AUTOSAR XML (schema 4-2-2)
package /STELLANTIS/EPT/ASWCs
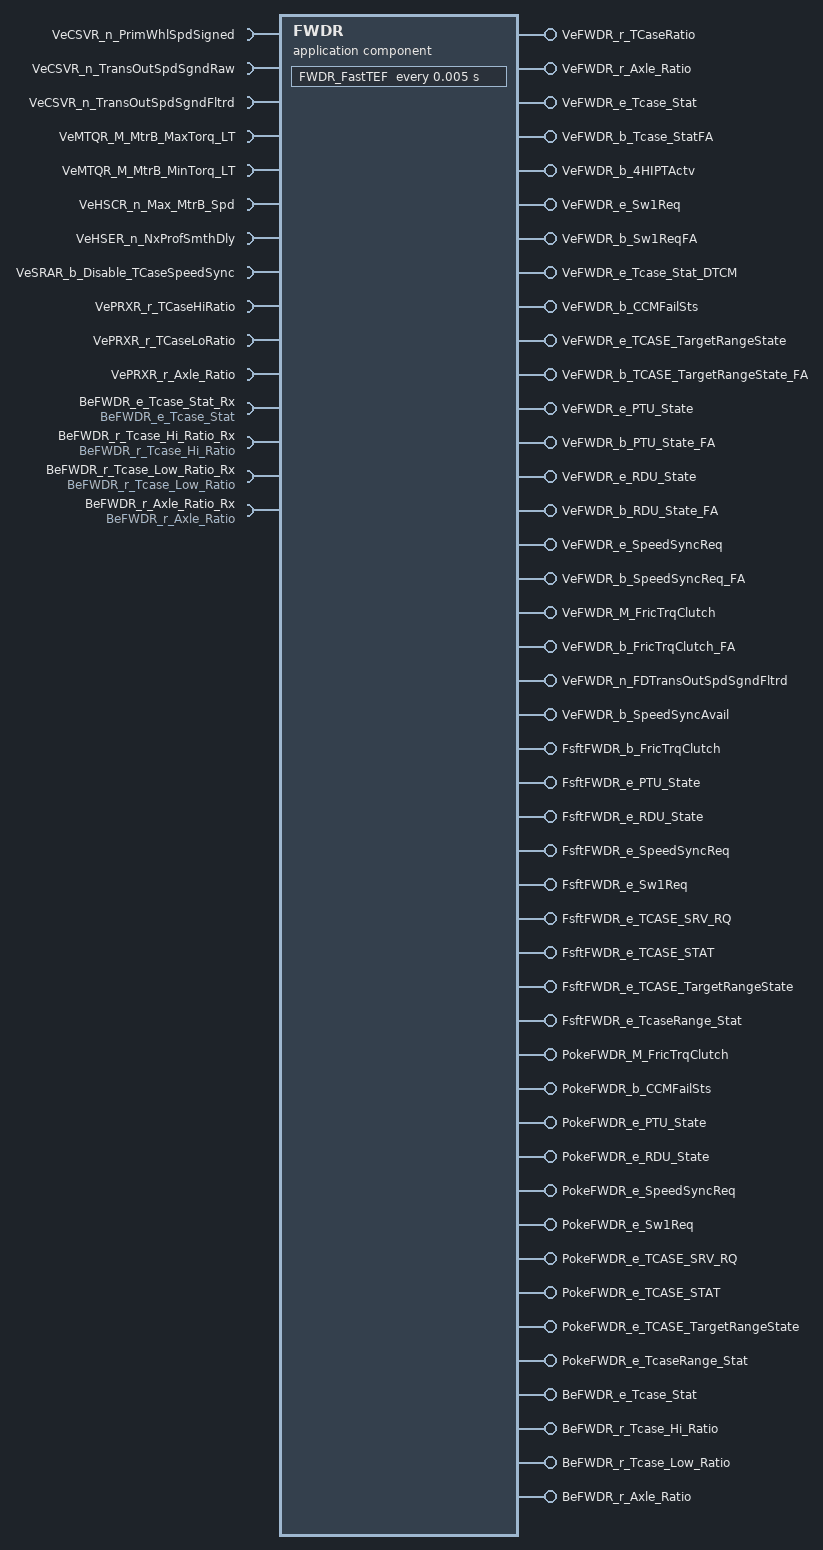
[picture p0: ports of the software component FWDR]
  application sw component type FWDR
    11 x require port, all with nonqueued-receiver-com-spec{data-element=Value, init-value=0}:
      VeCSVR_n_PrimWhlSpdSigned: required-interface=VeCSVR_n_PrimWhlSpdSigned
      VeCSVR_n_TransOutSpdSgndRaw: required-interface=VeCSVR_n_TransOutSpdSgndRaw
      VeCSVR_n_TransOutSpdSgndFltrd: required-interface=VeCSVR_n_TransOutSpdSgndFltrd
      VeMTQR_M_MtrB_MaxTorq_LT: required-interface=VeMTQR_M_MtrB_MaxTorq_LT
      VeMTQR_M_MtrB_MinTorq_LT: required-interface=VeMTQR_M_MtrB_MinTorq_LT
      VeHSCR_n_Max_MtrB_Spd: required-interface=VeHSCR_n_Max_MtrB_Spd
      VeHSER_n_NxProfSmthDly: required-interface=VeHSER_n_NxProfSmthDly
      VeSRAR_b_Disable_TCaseSpeedSync: required-interface=VeSRAR_b_Disable_TCaseSpeedSync
      VePRXR_r_TCaseHiRatio: required-interface=VePRXR_r_TCaseHiRatio
      VePRXR_r_TCaseLoRatio: required-interface=VePRXR_r_TCaseLoRatio
      VePRXR_r_Axle_Ratio: required-interface=VePRXR_r_Axle_Ratio
    40 x provide port:
      VeFWDR_r_TCaseRatio: nonqueued-sender-com-spec{data-element=Value, init-value=0}, provided-interface=VeFWDR_r_TCaseRatio
      VeFWDR_r_Axle_Ratio: nonqueued-sender-com-spec{data-element=Value, init-value=0}, provided-interface=VeFWDR_r_Axle_Ratio
      VeFWDR_e_Tcase_Stat: nonqueued-sender-com-spec{data-element=Value, init-value=CeFWDR_e_ShiftINProg}, provided-interface=VeFWDR_e_Tcase_Stat
      VeFWDR_b_Tcase_StatFA: nonqueued-sender-com-spec{data-element=Value, init-value=0}, provided-interface=VeFWDR_b_Tcase_StatFA
      VeFWDR_b_4HIPTActv: nonqueued-sender-com-spec{data-element=Value, init-value=0}, provided-interface=VeFWDR_b_4HIPTActv
      VeFWDR_e_Sw1Req: nonqueued-sender-com-spec{data-element=Value, init-value=CeFWDR_e_NotPSD}, provided-interface=VeFWDR_e_Sw1Req
      VeFWDR_b_Sw1ReqFA: nonqueued-sender-com-spec{data-element=Value, init-value=0}, provided-interface=VeFWDR_b_Sw1ReqFA
      VeFWDR_e_Tcase_Stat_DTCM: nonqueued-sender-com-spec{data-element=Value, init-value=CeFWDR_e_ShiftINProg}, provided-interface=VeFWDR_e_Tcase_Stat_DTCM
      VeFWDR_b_CCMFailSts: nonqueued-sender-com-spec{data-element=Value, init-value=0}, provided-interface=VeFWDR_b_CCMFailSts
      VeFWDR_e_TCASE_TargetRangeState: nonqueued-sender-com-spec{data-element=Value, init-value=CeFWDR_e_TRS_High}, provided-interface=VeFWDR_e_TCASE_TargetRangeState
      VeFWDR_b_TCASE_TargetRangeState_FA: nonqueued-sender-com-spec{data-element=Value, init-value=0}, provided-interface=VeFWDR_b_TCASE_TargetRangeState_FA
      VeFWDR_e_PTU_State: nonqueued-sender-com-spec{data-element=Value, init-value=CeFWDR_e_PTU_SNA}, provided-interface=VeFWDR_e_PTU_State
      VeFWDR_b_PTU_State_FA: nonqueued-sender-com-spec{data-element=Value, init-value=0}, provided-interface=VeFWDR_b_PTU_State_FA
      VeFWDR_e_RDU_State: nonqueued-sender-com-spec{data-element=Value, init-value=CeFWDR_e_RDU_SNA}, provided-interface=VeFWDR_e_RDU_State
      VeFWDR_b_RDU_State_FA: nonqueued-sender-com-spec{data-element=Value, init-value=0}, provided-interface=VeFWDR_b_RDU_State_FA
      VeFWDR_e_SpeedSyncReq: nonqueued-sender-com-spec{data-element=Value, init-value=CeFWDR_e_SSR_Inactive}, provided-interface=VeFWDR_e_SpeedSyncReq
      VeFWDR_b_SpeedSyncReq_FA: nonqueued-sender-com-spec{data-element=Value, init-value=0}, provided-interface=VeFWDR_b_SpeedSyncReq_FA
      VeFWDR_M_FricTrqClutch: nonqueued-sender-com-spec{data-element=Value, init-value=0}, provided-interface=VeFWDR_M_FricTrqClutch
      VeFWDR_b_FricTrqClutch_FA: nonqueued-sender-com-spec{data-element=Value, init-value=0}, provided-interface=VeFWDR_b_FricTrqClutch_FA
      VeFWDR_n_FDTransOutSpdSgndFltrd: nonqueued-sender-com-spec{data-element=Value, init-value=0}, provided-interface=VeFWDR_n_FDTransOutSpdSgndFltrd
      VeFWDR_b_SpeedSyncAvail: nonqueued-sender-com-spec{data-element=Value, init-value=0}, provided-interface=VeFWDR_b_SpeedSyncAvail
      FsftFWDR_b_FricTrqClutch: server-com-spec=FsftFWDR_b_FricTrqClutch, provided-interface=FsftFWDR_b_FricTrqClutch
      FsftFWDR_e_PTU_State: server-com-spec=FsftFWDR_e_PTU_State, provided-interface=FsftFWDR_e_PTU_State
      FsftFWDR_e_RDU_State: server-com-spec=FsftFWDR_e_RDU_State, provided-interface=FsftFWDR_e_RDU_State
      FsftFWDR_e_SpeedSyncReq: server-com-spec=FsftFWDR_e_SpeedSyncReq, provided-interface=FsftFWDR_e_SpeedSyncReq
      FsftFWDR_e_Sw1Req: server-com-spec=FsftFWDR_e_Sw1Req, provided-interface=FsftFWDR_e_Sw1Req
      FsftFWDR_e_TCASE_SRV_RQ: server-com-spec=FsftFWDR_e_TCASE_SRV_RQ, provided-interface=FsftFWDR_e_TCASE_SRV_RQ
      FsftFWDR_e_TCASE_STAT: server-com-spec=FsftFWDR_e_TCASE_STAT, provided-interface=FsftFWDR_e_TCASE_STAT
      FsftFWDR_e_TCASE_TargetRangeState: server-com-spec=FsftFWDR_e_TCASE_TargetRangeState, provided-interface=FsftFWDR_e_TCASE_TargetRangeState
      FsftFWDR_e_TcaseRange_Stat: server-com-spec=FsftFWDR_e_TcaseRange_Stat, provided-interface=FsftFWDR_e_TcaseRange_Stat
      PokeFWDR_M_FricTrqClutch: server-com-spec{operation=PokeFWDR_M_FricTrqClutch, queue-length=1}, provided-interface=PokeFWDR_M_FricTrqClutch
      PokeFWDR_b_CCMFailSts: server-com-spec{operation=PokeFWDR_b_CCMFailSts, queue-length=1}, provided-interface=PokeFWDR_b_CCMFailSts
      PokeFWDR_e_PTU_State: server-com-spec{operation=PokeFWDR_e_PTU_State, queue-length=1}, provided-interface=PokeFWDR_e_PTU_State
      PokeFWDR_e_RDU_State: server-com-spec{operation=PokeFWDR_e_RDU_State, queue-length=1}, provided-interface=PokeFWDR_e_RDU_State
      PokeFWDR_e_SpeedSyncReq: server-com-spec{operation=PokeFWDR_e_SpeedSyncReq, queue-length=1}, provided-interface=PokeFWDR_e_SpeedSyncReq
      PokeFWDR_e_Sw1Req: server-com-spec{operation=PokeFWDR_e_Sw1Req, queue-length=1}, provided-interface=PokeFWDR_e_Sw1Req
      PokeFWDR_e_TCASE_SRV_RQ: server-com-spec{operation=PokeFWDR_e_TCASE_SRV_RQ, queue-length=1}, provided-interface=PokeFWDR_e_TCASE_SRV_RQ
      PokeFWDR_e_TCASE_STAT: server-com-spec{operation=PokeFWDR_e_TCASE_STAT, queue-length=1}, provided-interface=PokeFWDR_e_TCASE_STAT
      PokeFWDR_e_TCASE_TargetRangeState: server-com-spec{operation=PokeFWDR_e_TCASE_TargetRangeState, queue-length=1}, provided-interface=PokeFWDR_e_TCASE_TargetRangeState
      PokeFWDR_e_TcaseRange_Stat: server-com-spec{operation=PokeFWDR_e_TcaseRange_Stat, queue-length=1}, provided-interface=PokeFWDR_e_TcaseRange_Stat
    4 x require port:
      BeFWDR_e_Tcase_Stat_Rx: nv-require-com-spec{init-value=-10, variable=BeFWDR_e_Tcase_Stat}, required-interface=BeFWDR_e_Tcase_Stat
      BeFWDR_r_Tcase_Hi_Ratio_Rx: nv-require-com-spec{init-value=-10, variable=BeFWDR_r_Tcase_Hi_Ratio}, required-interface=BeFWDR_r_Tcase_Hi_Ratio
      BeFWDR_r_Tcase_Low_Ratio_Rx: nv-require-com-spec{init-value=-10, variable=BeFWDR_r_Tcase_Low_Ratio}, required-interface=BeFWDR_r_Tcase_Low_Ratio
      BeFWDR_r_Axle_Ratio_Rx: nv-require-com-spec{init-value=-10, variable=BeFWDR_r_Axle_Ratio}, required-interface=BeFWDR_r_Axle_Ratio
    4 x provide port:
      BeFWDR_e_Tcase_Stat: nv-provide-com-spec{ram-block-init-value=-10, variable=BeFWDR_e_Tcase_Stat}, provided-interface=BeFWDR_e_Tcase_Stat
      BeFWDR_r_Tcase_Hi_Ratio: nv-provide-com-spec{ram-block-init-value=-10, variable=BeFWDR_r_Tcase_Hi_Ratio}, provided-interface=BeFWDR_r_Tcase_Hi_Ratio
      BeFWDR_r_Tcase_Low_Ratio: nv-provide-com-spec{ram-block-init-value=-10, variable=BeFWDR_r_Tcase_Low_Ratio}, provided-interface=BeFWDR_r_Tcase_Low_Ratio
      BeFWDR_r_Axle_Ratio: nv-provide-com-spec{ram-block-init-value=-10, variable=BeFWDR_r_Axle_Ratio}, provided-interface=BeFWDR_r_Axle_Ratio
    behavior IB_FWDR: data-type-mapping=msADTtoIDTMapping, handle-termination-and-restart=NO-SUPPORT
      timing event Event_FastTEF: start-on-event=FWDR_FastTEF, period=0.005
      19 x operation invoked event:
        Event_FsftFWDR_b_FricTrqClutch: start-on-event=FsftFWDR_b_FricTrqClutch, operation=FsftFWDR_b_FricTrqClutch.FsftFWDR_b_FricTrqClutch
        Event_FsftFWDR_e_PTU_State: start-on-event=FsftFWDR_e_PTU_State, operation=FsftFWDR_e_PTU_State.FsftFWDR_e_PTU_State
        Event_FsftFWDR_e_RDU_State: start-on-event=FsftFWDR_e_RDU_State, operation=FsftFWDR_e_RDU_State.FsftFWDR_e_RDU_State
        Event_FsftFWDR_e_SpeedSyncReq: start-on-event=FsftFWDR_e_SpeedSyncReq, operation=FsftFWDR_e_SpeedSyncReq.FsftFWDR_e_SpeedSyncReq
        Event_FsftFWDR_e_Sw1Req: start-on-event=FsftFWDR_e_Sw1Req, operation=FsftFWDR_e_Sw1Req.FsftFWDR_e_Sw1Req
        Event_FsftFWDR_e_TCASE_SRV_RQ: start-on-event=FsftFWDR_e_TCASE_SRV_RQ, operation=FsftFWDR_e_TCASE_SRV_RQ.FsftFWDR_e_TCASE_SRV_RQ
        Event_FsftFWDR_e_TCASE_STAT: start-on-event=FsftFWDR_e_TCASE_STAT, operation=FsftFWDR_e_TCASE_STAT.FsftFWDR_e_TCASE_STAT
        Event_FsftFWDR_e_TCASE_TargetRangeState: start-on-event=FsftFWDR_e_TCASE_TargetRangeState, operation=FsftFWDR_e_TCASE_TargetRangeState.FsftFWDR_e_TCASE_TargetRangeState
        Event_FsftFWDR_e_TcaseRange_Stat: start-on-event=FsftFWDR_e_TcaseRange_Stat, operation=FsftFWDR_e_TcaseRange_Stat.FsftFWDR_e_TcaseRange_Stat
        Event_PokeFWDR_M_FricTrqClutch: start-on-event=PokeFWDR_M_FricTrqClutch, operation=PokeFWDR_M_FricTrqClutch.PokeFWDR_M_FricTrqClutch
        Event_PokeFWDR_b_CCMFailSts: start-on-event=PokeFWDR_b_CCMFailSts, operation=PokeFWDR_b_CCMFailSts.PokeFWDR_b_CCMFailSts
        Event_PokeFWDR_e_PTU_State: start-on-event=PokeFWDR_e_PTU_State, operation=PokeFWDR_e_PTU_State.PokeFWDR_e_PTU_State
        Event_PokeFWDR_e_RDU_State: start-on-event=PokeFWDR_e_RDU_State, operation=PokeFWDR_e_RDU_State.PokeFWDR_e_RDU_State
        Event_PokeFWDR_e_SpeedSyncReq: start-on-event=PokeFWDR_e_SpeedSyncReq, operation=PokeFWDR_e_SpeedSyncReq.PokeFWDR_e_SpeedSyncReq
        Event_PokeFWDR_e_Sw1Req: start-on-event=PokeFWDR_e_Sw1Req, operation=PokeFWDR_e_Sw1Req.PokeFWDR_e_Sw1Req
        Event_PokeFWDR_e_TCASE_SRV_RQ: start-on-event=PokeFWDR_e_TCASE_SRV_RQ, operation=PokeFWDR_e_TCASE_SRV_RQ.PokeFWDR_e_TCASE_SRV_RQ
        Event_PokeFWDR_e_TCASE_STAT: start-on-event=PokeFWDR_e_TCASE_STAT, operation=PokeFWDR_e_TCASE_STAT.PokeFWDR_e_TCASE_STAT
        Event_PokeFWDR_e_TCASE_TargetRangeState: start-on-event=PokeFWDR_e_TCASE_TargetRangeState, operation=PokeFWDR_e_TCASE_TargetRangeState.PokeFWDR_e_TCASE_TargetRangeState
        Event_PokeFWDR_e_TcaseRange_Stat: start-on-event=PokeFWDR_e_TcaseRange_Stat, operation=PokeFWDR_e_TcaseRange_Stat.PokeFWDR_e_TcaseRange_Stat
      init event Event_FWDR_ac_Init: start-on-event=FWDR_ac_Init
      init event Event_PwrOn: start-on-event=FWDR_PwrOn
      init event Event_PwrOff: start-on-event=FWDR_PwrOff
      explicit-inter-runnable-variables:
        5 x data, all with category=VALUE, sw-calibration-access=READ-ONLY:
          VeFWDI_e_Tcase_Stat_init_write_IRV: type=TeFWDR_e_TrnsfrCaseRange, init-value=CeFWDR_e_ShiftINProg
          VeFWDI_b_Tcase_StatFA_init_write_IRV: type=Boolean, init-value=0
          VeFWDI_e_Tcase_Stat_DTCM_init_write_IRV: type=TeFWDR_e_TrnsfrCaseRange, init-value=CeFWDR_e_ShiftINProg
          VeFWDI_e_Tcase_Srv_Rq_init_write_IRV: type=TeFWDR_e_Tcase_Srv_Rq, init-value=CeFWDR_e_OFF
          VeFWDI_b_Tcase_Stat_DTCMFA_Init_write_IRV: type=Boolean, init-value=0
      23 x runnable:
        FWDR_ac_Init
          data-send-points:
            21 x access:
              OUT_VeFWDR_r_TCaseRatio_Value: accessed-variable=VeFWDR_r_TCaseRatio.Value
              OUT_VeFWDR_r_Axle_Ratio_Value: accessed-variable=VeFWDR_r_Axle_Ratio.Value
              OUT_VeFWDR_e_Tcase_Stat_Value: accessed-variable=VeFWDR_e_Tcase_Stat.Value
              OUT_VeFWDR_b_Tcase_StatFA_Value: accessed-variable=VeFWDR_b_Tcase_StatFA.Value
              OUT_VeFWDR_b_4HIPTActv_Value: accessed-variable=VeFWDR_b_4HIPTActv.Value
              OUT_VeFWDR_e_Sw1Req_Value: accessed-variable=VeFWDR_e_Sw1Req.Value
              OUT_VeFWDR_b_Sw1ReqFA_Value: accessed-variable=VeFWDR_b_Sw1ReqFA.Value
              OUT_VeFWDR_e_Tcase_Stat_DTCM_Value: accessed-variable=VeFWDR_e_Tcase_Stat_DTCM.Value
              OUT_VeFWDR_b_CCMFailSts_Value: accessed-variable=VeFWDR_b_CCMFailSts.Value
              OUT_VeFWDR_e_TCASE_TargetRangeState_Value: accessed-variable=VeFWDR_e_TCASE_TargetRangeState.Value
              OUT_VeFWDR_b_TCASE_TargetRangeState_FA_Value: accessed-variable=VeFWDR_b_TCASE_TargetRangeState_FA.Value
              OUT_VeFWDR_e_PTU_State_Value: accessed-variable=VeFWDR_e_PTU_State.Value
              OUT_VeFWDR_b_PTU_State_FA_Value: accessed-variable=VeFWDR_b_PTU_State_FA.Value
              OUT_VeFWDR_e_RDU_State_Value: accessed-variable=VeFWDR_e_RDU_State.Value
              OUT_VeFWDR_b_RDU_State_FA_Value: accessed-variable=VeFWDR_b_RDU_State_FA.Value
              OUT_VeFWDR_e_SpeedSyncReq_Value: accessed-variable=VeFWDR_e_SpeedSyncReq.Value
              OUT_VeFWDR_b_SpeedSyncReq_FA_Value: accessed-variable=VeFWDR_b_SpeedSyncReq_FA.Value
              OUT_VeFWDR_M_FricTrqClutch_Value: accessed-variable=VeFWDR_M_FricTrqClutch.Value
              OUT_VeFWDR_b_FricTrqClutch_FA_Value: accessed-variable=VeFWDR_b_FricTrqClutch_FA.Value
              OUT_VeFWDR_n_FDTransOutSpdSgndFltrd_Value: accessed-variable=VeFWDR_n_FDTransOutSpdSgndFltrd.Value
              OUT_VeFWDR_b_SpeedSyncAvail_Value: accessed-variable=VeFWDR_b_SpeedSyncAvail.Value
        FWDR_PwrOn
          data-receive-point-by-arguments:
            4 x access:
              IN_BeFWDR_e_Tcase_Stat_Rx_BeFWDR_e_Tcase_Stat: accessed-variable=BeFWDR_e_Tcase_Stat_Rx.BeFWDR_e_Tcase_Stat
              IN_BeFWDR_r_Axle_Ratio_Rx_BeFWDR_r_Axle_Ratio: accessed-variable=BeFWDR_r_Axle_Ratio_Rx.BeFWDR_r_Axle_Ratio
              IN_BeFWDR_r_Tcase_Hi_Ratio_Rx_BeFWDR_r_Tcase_Hi_Ratio: accessed-variable=BeFWDR_r_Tcase_Hi_Ratio_Rx.BeFWDR_r_Tcase_Hi_Ratio
              IN_BeFWDR_r_Tcase_Low_Ratio_Rx_BeFWDR_r_Tcase_Low_Ratio: accessed-variable=BeFWDR_r_Tcase_Low_Ratio_Rx.BeFWDR_r_Tcase_Low_Ratio
          data-send-points:
            21 x access:
              OUT_VeFWDR_e_Tcase_Stat_DTCM_Value: accessed-variable=VeFWDR_e_Tcase_Stat_DTCM.Value
              OUT_VeFWDR_b_Sw1ReqFA_Value: accessed-variable=VeFWDR_b_Sw1ReqFA.Value
              OUT_VeFWDR_e_Sw1Req_Value: accessed-variable=VeFWDR_e_Sw1Req.Value
              OUT_VeFWDR_b_CCMFailSts_Value: accessed-variable=VeFWDR_b_CCMFailSts.Value
              OUT_VeFWDR_b_TCASE_TargetRangeState_FA_Value: accessed-variable=VeFWDR_b_TCASE_TargetRangeState_FA.Value
              OUT_VeFWDR_e_TCASE_TargetRangeState_Value: accessed-variable=VeFWDR_e_TCASE_TargetRangeState.Value
              OUT_VeFWDR_b_PTU_State_FA_Value: accessed-variable=VeFWDR_b_PTU_State_FA.Value
              OUT_VeFWDR_e_PTU_State_Value: accessed-variable=VeFWDR_e_PTU_State.Value
              OUT_VeFWDR_b_RDU_State_FA_Value: accessed-variable=VeFWDR_b_RDU_State_FA.Value
              OUT_VeFWDR_e_RDU_State_Value: accessed-variable=VeFWDR_e_RDU_State.Value
              OUT_VeFWDR_b_SpeedSyncReq_FA_Value: accessed-variable=VeFWDR_b_SpeedSyncReq_FA.Value
              OUT_VeFWDR_e_SpeedSyncReq_Value: accessed-variable=VeFWDR_e_SpeedSyncReq.Value
              OUT_VeFWDR_b_FricTrqClutch_FA_Value: accessed-variable=VeFWDR_b_FricTrqClutch_FA.Value
              OUT_VeFWDR_M_FricTrqClutch_Value: accessed-variable=VeFWDR_M_FricTrqClutch.Value
              OUT_VeFWDR_r_TCaseRatio_Value: accessed-variable=VeFWDR_r_TCaseRatio.Value
              OUT_VeFWDR_r_Axle_Ratio_Value: accessed-variable=VeFWDR_r_Axle_Ratio.Value
              OUT_VeFWDR_e_Tcase_Stat_Value: accessed-variable=VeFWDR_e_Tcase_Stat.Value
              OUT_VeFWDR_b_Tcase_StatFA_Value: accessed-variable=VeFWDR_b_Tcase_StatFA.Value
              OUT_VeFWDR_b_4HIPTActv_Value: accessed-variable=VeFWDR_b_4HIPTActv.Value
              OUT_VeFWDR_n_FDTransOutSpdSgndFltrd_Value: accessed-variable=VeFWDR_n_FDTransOutSpdSgndFltrd.Value
              OUT_VeFWDR_b_SpeedSyncAvail_Value: accessed-variable=VeFWDR_b_SpeedSyncAvail.Value
          written-local-variables:
            5 x access:
              WV_VeFWDI_b_Tcase_StatFA_init_write_IRV: accessed-variable=VeFWDI_b_Tcase_StatFA_init_write_IRV
              WV_VeFWDI_b_Tcase_Stat_DTCMFA_Init_write_IRV: accessed-variable=VeFWDI_b_Tcase_Stat_DTCMFA_Init_write_IRV
              WV_VeFWDI_e_Tcase_Srv_Rq_init_write_IRV: accessed-variable=VeFWDI_e_Tcase_Srv_Rq_init_write_IRV
              WV_VeFWDI_e_Tcase_Stat_DTCM_init_write_IRV: accessed-variable=VeFWDI_e_Tcase_Stat_DTCM_init_write_IRV
              WV_VeFWDI_e_Tcase_Stat_init_write_IRV: accessed-variable=VeFWDI_e_Tcase_Stat_init_write_IRV
        FWDR_FastTEF
          data-receive-point-by-arguments:
            11 x access:
              IN_VeCSVR_n_PrimWhlSpdSigned_Value: accessed-variable=VeCSVR_n_PrimWhlSpdSigned.Value
              IN_VeCSVR_n_TransOutSpdSgndFltrd_Value: accessed-variable=VeCSVR_n_TransOutSpdSgndFltrd.Value
              IN_VeCSVR_n_TransOutSpdSgndRaw_Value: accessed-variable=VeCSVR_n_TransOutSpdSgndRaw.Value
              IN_VeHSCR_n_Max_MtrB_Spd_Value: accessed-variable=VeHSCR_n_Max_MtrB_Spd.Value
              IN_VeHSER_n_NxProfSmthDly_Value: accessed-variable=VeHSER_n_NxProfSmthDly.Value
              IN_VeMTQR_M_MtrB_MaxTorq_LT_Value: accessed-variable=VeMTQR_M_MtrB_MaxTorq_LT.Value
              IN_VeMTQR_M_MtrB_MinTorq_LT_Value: accessed-variable=VeMTQR_M_MtrB_MinTorq_LT.Value
              IN_VePRXR_r_Axle_Ratio_Value: accessed-variable=VePRXR_r_Axle_Ratio.Value
              IN_VePRXR_r_TCaseHiRatio_Value: accessed-variable=VePRXR_r_TCaseHiRatio.Value
              IN_VePRXR_r_TCaseLoRatio_Value: accessed-variable=VePRXR_r_TCaseLoRatio.Value
              IN_VeSRAR_b_Disable_TCaseSpeedSync_Value: accessed-variable=VeSRAR_b_Disable_TCaseSpeedSync.Value
          data-send-points:
            7 x access:
              OUT_VeFWDR_r_TCaseRatio_Value: accessed-variable=VeFWDR_r_TCaseRatio.Value
              OUT_VeFWDR_r_Axle_Ratio_Value: accessed-variable=VeFWDR_r_Axle_Ratio.Value
              OUT_VeFWDR_e_Tcase_Stat_Value: accessed-variable=VeFWDR_e_Tcase_Stat.Value
              OUT_VeFWDR_b_Tcase_StatFA_Value: accessed-variable=VeFWDR_b_Tcase_StatFA.Value
              OUT_VeFWDR_b_4HIPTActv_Value: accessed-variable=VeFWDR_b_4HIPTActv.Value
              OUT_VeFWDR_n_FDTransOutSpdSgndFltrd_Value: accessed-variable=VeFWDR_n_FDTransOutSpdSgndFltrd.Value
              OUT_VeFWDR_b_SpeedSyncAvail_Value: accessed-variable=VeFWDR_b_SpeedSyncAvail.Value
          read-local-variables:
            5 x access:
              RV_VeFWDI_b_Tcase_StatFA_init_write_IRV: accessed-variable=VeFWDI_b_Tcase_StatFA_init_write_IRV
              RV_VeFWDI_b_Tcase_Stat_DTCMFA_Init_write_IRV: accessed-variable=VeFWDI_b_Tcase_Stat_DTCMFA_Init_write_IRV
              RV_VeFWDI_e_Tcase_Srv_Rq_init_write_IRV: accessed-variable=VeFWDI_e_Tcase_Srv_Rq_init_write_IRV
              RV_VeFWDI_e_Tcase_Stat_DTCM_init_write_IRV: accessed-variable=VeFWDI_e_Tcase_Stat_DTCM_init_write_IRV
              RV_VeFWDI_e_Tcase_Stat_init_write_IRV: accessed-variable=VeFWDI_e_Tcase_Stat_init_write_IRV
        FWDR_PwrOff
          data-send-points:
            4 x access:
              OUT_BeFWDR_e_Tcase_Stat_BeFWDR_e_Tcase_Stat: accessed-variable=BeFWDR_e_Tcase_Stat.BeFWDR_e_Tcase_Stat
              OUT_BeFWDR_r_Tcase_Hi_Ratio_BeFWDR_r_Tcase_Hi_Ratio: accessed-variable=BeFWDR_r_Tcase_Hi_Ratio.BeFWDR_r_Tcase_Hi_Ratio
              OUT_BeFWDR_r_Tcase_Low_Ratio_BeFWDR_r_Tcase_Low_Ratio: accessed-variable=BeFWDR_r_Tcase_Low_Ratio.BeFWDR_r_Tcase_Low_Ratio
              OUT_BeFWDR_r_Axle_Ratio_BeFWDR_r_Axle_Ratio: accessed-variable=BeFWDR_r_Axle_Ratio.BeFWDR_r_Axle_Ratio
        FsftFWDR_b_FricTrqClutch
          data-send-points:
            access OUT_VeFWDR_b_FricTrqClutch_FA_Value: accessed-variable=VeFWDR_b_FricTrqClutch_FA.Value
        FsftFWDR_e_PTU_State
          data-send-points:
            access OUT_VeFWDR_e_PTU_State_Value: accessed-variable=VeFWDR_e_PTU_State.Value
            access OUT_VeFWDR_b_PTU_State_FA_Value: accessed-variable=VeFWDR_b_PTU_State_FA.Value
        FsftFWDR_e_RDU_State
          data-send-points:
            access OUT_VeFWDR_e_RDU_State_Value: accessed-variable=VeFWDR_e_RDU_State.Value
            access OUT_VeFWDR_b_RDU_State_FA_Value: accessed-variable=VeFWDR_b_RDU_State_FA.Value
        FsftFWDR_e_SpeedSyncReq
          data-send-points:
            access OUT_VeFWDR_e_SpeedSyncReq_Value: accessed-variable=VeFWDR_e_SpeedSyncReq.Value
            access OUT_VeFWDR_b_SpeedSyncReq_FA_Value: accessed-variable=VeFWDR_b_SpeedSyncReq_FA.Value
        FsftFWDR_e_Sw1Req
          data-send-points:
            access OUT_VeFWDR_e_Sw1Req_Value: accessed-variable=VeFWDR_e_Sw1Req.Value
            access OUT_VeFWDR_b_Sw1ReqFA_Value: accessed-variable=VeFWDR_b_Sw1ReqFA.Value
        FsftFWDR_e_TCASE_SRV_RQ
          written-local-variables:
            access WV_VeFWDI_e_Tcase_Srv_Rq_init_write_IRV: accessed-variable=VeFWDI_e_Tcase_Srv_Rq_init_write_IRV
        FsftFWDR_e_TCASE_STAT
          data-send-points:
            access OUT_VeFWDR_e_Tcase_Stat_DTCM_Value: accessed-variable=VeFWDR_e_Tcase_Stat_DTCM.Value
          written-local-variables:
            access WV_VeFWDI_b_Tcase_Stat_DTCMFA_Init_write_IRV: accessed-variable=VeFWDI_b_Tcase_Stat_DTCMFA_Init_write_IRV
            access WV_VeFWDI_e_Tcase_Stat_DTCM_init_write_IRV: accessed-variable=VeFWDI_e_Tcase_Stat_DTCM_init_write_IRV
        FsftFWDR_e_TCASE_TargetRangeState
          data-send-points:
            access OUT_VeFWDR_e_TCASE_TargetRangeState_Value: accessed-variable=VeFWDR_e_TCASE_TargetRangeState.Value
            access OUT_VeFWDR_b_TCASE_TargetRangeState_FA_Value: accessed-variable=VeFWDR_b_TCASE_TargetRangeState_FA.Value
        FsftFWDR_e_TcaseRange_Stat
          written-local-variables:
            access WV_VeFWDI_b_Tcase_StatFA_init_write_IRV: accessed-variable=VeFWDI_b_Tcase_StatFA_init_write_IRV
        PokeFWDR_M_FricTrqClutch
          data-send-points:
            access OUT_VeFWDR_M_FricTrqClutch_Value: accessed-variable=VeFWDR_M_FricTrqClutch.Value
            access OUT_VeFWDR_b_FricTrqClutch_FA_Value: accessed-variable=VeFWDR_b_FricTrqClutch_FA.Value
        PokeFWDR_b_CCMFailSts
          data-send-points:
            access OUT_VeFWDR_b_CCMFailSts_Value: accessed-variable=VeFWDR_b_CCMFailSts.Value
        PokeFWDR_e_PTU_State
          data-send-points:
            access OUT_VeFWDR_e_PTU_State_Value: accessed-variable=VeFWDR_e_PTU_State.Value
            access OUT_VeFWDR_b_PTU_State_FA_Value: accessed-variable=VeFWDR_b_PTU_State_FA.Value
        PokeFWDR_e_RDU_State
          data-send-points:
            access OUT_VeFWDR_e_RDU_State_Value: accessed-variable=VeFWDR_e_RDU_State.Value
            access OUT_VeFWDR_b_RDU_State_FA_Value: accessed-variable=VeFWDR_b_RDU_State_FA.Value
        PokeFWDR_e_SpeedSyncReq
          data-send-points:
            access OUT_VeFWDR_e_SpeedSyncReq_Value: accessed-variable=VeFWDR_e_SpeedSyncReq.Value
            access OUT_VeFWDR_b_SpeedSyncReq_FA_Value: accessed-variable=VeFWDR_b_SpeedSyncReq_FA.Value
        PokeFWDR_e_Sw1Req
          data-send-points:
            access OUT_VeFWDR_e_Sw1Req_Value: accessed-variable=VeFWDR_e_Sw1Req.Value
            access OUT_VeFWDR_b_Sw1ReqFA_Value: accessed-variable=VeFWDR_b_Sw1ReqFA.Value
        PokeFWDR_e_TCASE_SRV_RQ
          written-local-variables:
            access WV_VeFWDI_e_Tcase_Srv_Rq_init_write_IRV: accessed-variable=VeFWDI_e_Tcase_Srv_Rq_init_write_IRV
        PokeFWDR_e_TCASE_STAT
          data-send-points:
            access OUT_VeFWDR_e_Tcase_Stat_DTCM_Value: accessed-variable=VeFWDR_e_Tcase_Stat_DTCM.Value
          written-local-variables:
            access WV_VeFWDI_b_Tcase_Stat_DTCMFA_Init_write_IRV: accessed-variable=VeFWDI_b_Tcase_Stat_DTCMFA_Init_write_IRV
            access WV_VeFWDI_e_Tcase_Stat_DTCM_init_write_IRV: accessed-variable=VeFWDI_e_Tcase_Stat_DTCM_init_write_IRV
        PokeFWDR_e_TCASE_TargetRangeState
          data-send-points:
            access OUT_VeFWDR_e_TCASE_TargetRangeState_Value: accessed-variable=VeFWDR_e_TCASE_TargetRangeState.Value
            access OUT_VeFWDR_b_TCASE_TargetRangeState_FA_Value: accessed-variable=VeFWDR_b_TCASE_TargetRangeState_FA.Value
        PokeFWDR_e_TcaseRange_Stat
          written-local-variables:
            access WV_VeFWDI_b_Tcase_StatFA_init_write_IRV: accessed-variable=VeFWDI_b_Tcase_StatFA_init_write_IRV
            access WV_VeFWDI_e_Tcase_Stat_init_write_IRV: accessed-variable=VeFWDI_e_Tcase_Stat_init_write_IRV
